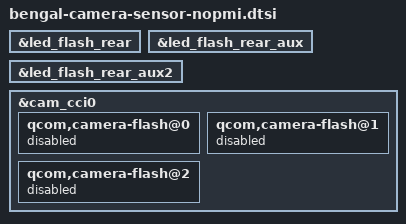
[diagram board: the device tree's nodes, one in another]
&led_flash_rear {
	/delete-property/ flash-source;
	/delete-property/ torch-source;
	/delete-property/ switch-source;
};

&led_flash_rear_aux {
	/delete-property/ flash-source;
	/delete-property/ torch-source;
	/delete-property/ switch-source;
};

&led_flash_rear_aux2 {
	/delete-property/ flash-source;
	/delete-property/ torch-source;
	/delete-property/ switch-source;
};

&cam_cci0 {
	qcom,camera-flash@0 {
		status = "disabled";
	};
	qcom,camera-flash@1 {
		status = "disabled";
	};
	qcom,camera-flash@2 {
		status = "disabled";
	};
};
